VERSION ""

NS_ :

BS_:

BU_: RearSuspension FrontSuspension Engine Gateway

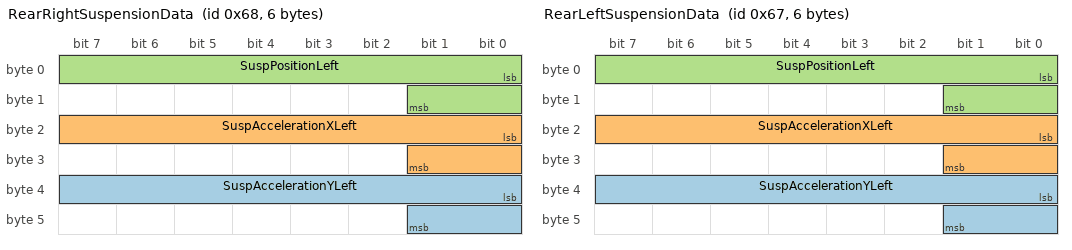
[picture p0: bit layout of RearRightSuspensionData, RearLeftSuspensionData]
BO_ 104 RearRightSuspensionData: 6 RearSuspension
 SG_ SuspAccelerationYLeft : 32|10@1- (0.05,0) [-512|511] "m/s2" Vector__XXX
 SG_ SuspAccelerationXLeft : 16|10@1- (0.05,0) [-25.6|25.55] "m/s2" Vector__XXX
 SG_ SuspPositionLeft : 0|10@1- (1,0) [-512|511] "cm" Vector__XXX

BO_ 103 RearLeftSuspensionData: 6 RearSuspension
 SG_ SuspAccelerationYLeft : 32|10@1- (0.05,0) [-512|511] "m/s2" Vector__XXX
 SG_ SuspAccelerationXLeft : 16|10@1- (0.05,0) [-25.6|25.55] "m/s2" Vector__XXX
 SG_ SuspPositionLeft : 0|10@1- (1,0) [-512|511] "cm" Vector__XXX

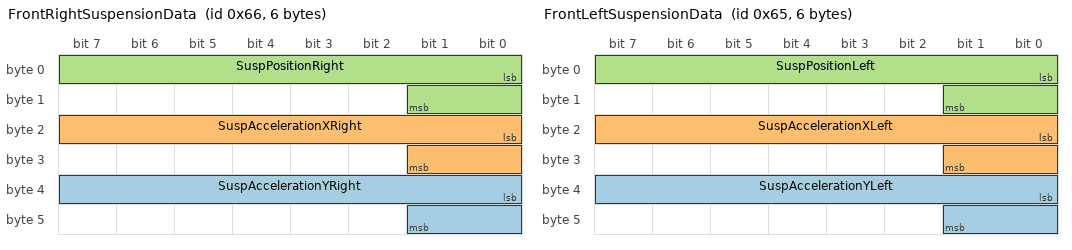
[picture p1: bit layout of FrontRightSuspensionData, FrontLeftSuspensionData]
BO_ 102 FrontRightSuspensionData: 6 FrontSuspension
 SG_ SuspAccelerationYRight : 32|10@1- (0.05,0) [-512|511] "m/s2" Vector__XXX
 SG_ SuspAccelerationXRight : 16|10@1- (0.05,0) [-25.6|25.55] "m/s2" Vector__XXX
 SG_ SuspPositionRight : 0|10@1- (1,0) [-512|511] "cm" Vector__XXX

BO_ 101 FrontLeftSuspensionData: 6 FrontSuspension
 SG_ SuspAccelerationYLeft : 32|10@1- (0.05,0) [-512|511] "m/s2" Vector__XXX
 SG_ SuspAccelerationXLeft : 16|10@1- (0.05,0) [-25.6|25.55] "m/s2" Vector__XXX
 SG_ SuspPositionLeft : 0|10@1- (1,0) [-512|511] "cm" Vector__XXX

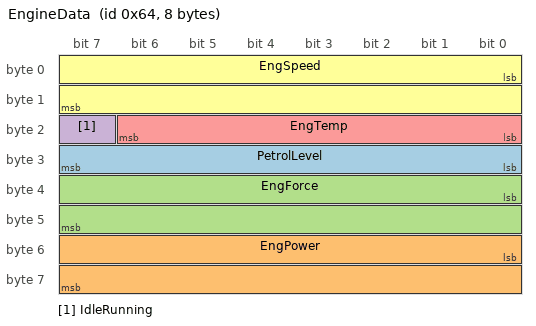
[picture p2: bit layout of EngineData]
BO_ 100 EngineData: 8 Engine
 SG_ PetrolLevel : 24|8@1+ (1,0) [0|255] "l"  Gateway
 SG_ EngPower : 48|16@1+ (0.01,0) [0|150] "kW"  Gateway
 SG_ EngForce : 32|16@1+ (1,0) [0|0] "N"  Gateway
 SG_ IdleRunning : 23|1@1+ (1,0) [0|0] ""  Gateway
 SG_ EngTemp : 16|7@1+ (2,-50) [-50|150] "degC"  Gateway
 SG_ EngSpeed : 0|16@1+ (1,0) [0|8000] "rpm"  Gateway

CM_ "CAN communication matrix for power train electronics ******************************************************* implemented: turn lights, warning lights, windows";
BA_DEF_  "BusType" STRING ;
BA_DEF_DEF_  "BusType" "";
BA_ "BusType" "CAN";
VAL_ 100 IdleRunning 0 "Running" 1 "Idle" ;
